AUTOSAR XML (schema 19-11)
standard types defined: Float32, UInt8
package /Components
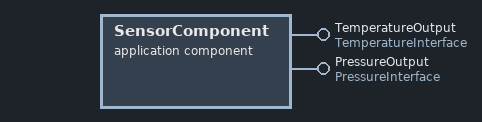
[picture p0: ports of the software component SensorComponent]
  application sw component type SensorComponent: category=APPLICATION_LAYER
    provide port TemperatureOutput: provided-interface=TemperatureInterface
    provide port PressureOutput: provided-interface=PressureInterface
package /Interfaces
  sender receiver interface TemperatureInterface
    data TempValue: type=Float32
    data TempUnit: type=UInt8
  sender receiver interface PressureInterface
    data PressureValue: type=Float32
